AUTOSAR XML (schema 4-0-3)
standard types defined: UInt32
package /PATAC/MSM/ComponentTypes
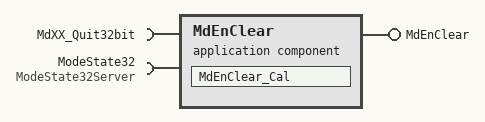
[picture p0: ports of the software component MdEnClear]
  application sw component type MdEnClear
    provide port MdEnClear: server-com-spec{operation=Cal, queue-length=1}, provided-interface=MdEnClear
    require port MdXX_Quit32bit: nonqueued-receiver-com-spec{data-element=Val, filter=data-filter-type=ALWAYS, init-value=0}, required-interface=MdXX_Quit32bit
    require port ModeState32: required-com-specs=[Clear, Get, Set], required-interface=ModeState32Server
    behavior MdEnClear_InternalBehavior
      operation invoked event OIT_MdEnClear_Cal_MdEnClear_Cal: start-on-event=MdEnClear_Cal, operation=MdEnClear.Cal
      runnable MdEnClear_Cal
        data-receive-point-by-arguments:
          access REC_MdXX_Quit32bit_Val: accessed-variable=MdXX_Quit32bit.Val
        sync call SC_ModeState32_Clear: operation=ModeState32.Clear, timeout=0
        sync call SC_ModeState32_Get: operation=ModeState32.Get, timeout=0
  swc implementation MdEnClear_Implementation: behavior=MdEnClear_InternalBehavior
    code-descriptors:
      code Default: artifact-descriptors=autosar-engineering-object={short-label=Default, category=SWSRC}
package /PATAC/MSM/ModeAdjust/PortInterface
  client server interface MdEnClear
    operation Cal
  client server interface ModeState32Server
    operation Clear
      arg ClearBit: type=UInt32, direction=IN, server-argument-impl-policy=USE-ARGUMENT-TYPE
    operation Get
      arg MdEn32: type=UInt32, direction=OUT, server-argument-impl-policy=USE-ARGUMENT-TYPE
    operation Set
      arg SetBit: type=UInt32, direction=IN, server-argument-impl-policy=USE-ARGUMENT-TYPE
  sender receiver interface MdXX_Quit32bit: invalidation-policy{data-element=Val, handle-invalid=DONT-INVALIDATE}
    data Val: type=UInt32
